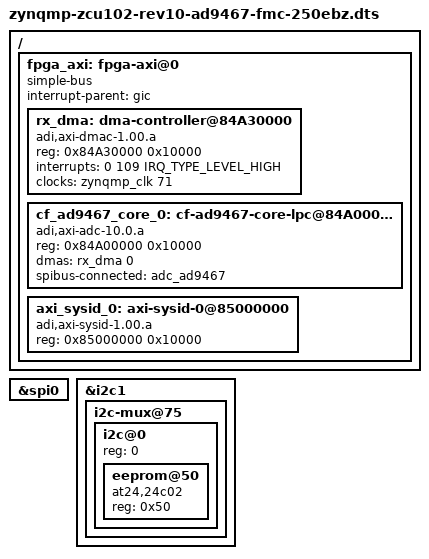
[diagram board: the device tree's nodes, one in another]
// SPDX-License-Identifier: GPL-2.0
/*
 * Analog Devices AD9467
 * https://wiki.analog.com/resources/tools-software/linux-drivers/iio-adc/axi-adc-hdl
 * https://wiki.analog.com/resources/eval/ad9467-fmc-250ebz
 * https://wiki.analog.com/resources/fpga/xilinx/fmc/ad9467
 *
 * hdl_project: <ad9467_fmc/zcu102>
 * board_revision: <>
 *
 * Copyright (C) 2025 Analog Devices Inc.
 */
/dts-v1/;

#include "zynqmp-zcu102-rev1.0.dts"
#include <dt-bindings/interrupt-controller/irq.h>

/ {
	fpga_axi: fpga-axi@0 {
		interrupt-parent = <&gic>;
		compatible = "simple-bus";
		#address-cells = <0x1>;
		#size-cells = <0x1>;
		ranges = <0 0 0 0xffffffff>;

		rx_dma: dma-controller@84A30000 {
			compatible = "adi,axi-dmac-1.00.a";
			reg = <0x84A30000 0x10000>;
			#dma-cells = <1>;
			interrupts = <0 109 IRQ_TYPE_LEVEL_HIGH>;
			clocks = <&zynqmp_clk 71>;
		};

		cf_ad9467_core_0: cf-ad9467-core-lpc@84A00000 {
			compatible = "adi,axi-adc-10.0.a", "adi,axi-ad9467-1.0";
			reg = <0x84A00000 0x10000>;
			dmas = <&rx_dma 0>;
			dma-names = "rx";

			spibus-connected = <&adc_ad9467>;
		};

		axi_sysid_0: axi-sysid-0@85000000 {
			compatible = "adi,axi-sysid-1.00.a";
			reg = <0x85000000 0x10000>;
		};
	};
};

&spi0 {
	status = "okay";
};

&i2c1 {
	i2c-mux@75 {
		i2c@0 {
			#address-cells = <1>;
			#size-cells = <0>;
			reg = <0>;

			eeprom@50 {
				compatible = "at24,24c02";
				reg = <0x50>;
			};
		};
	};
};

#define fmc_spi spi0

#include "adi-ad9467-fmc-250ebz.dtsi"
